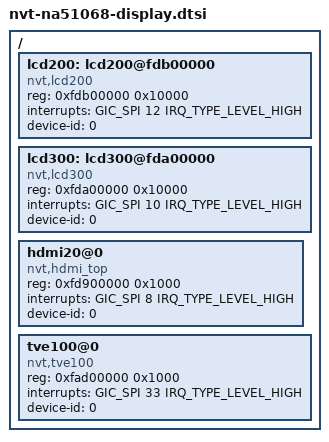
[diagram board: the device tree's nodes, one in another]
/*
 * Novatek Ltd. NA51068 BSP part of dts
 *
 * Cortex-A9
 *
 */

/ {    
    lcd200: lcd200@fdb00000 {
        compatible = "nvt,lcd200";
        reg = <0xfdb00000 0x10000>;
        interrupts = <GIC_SPI 12 IRQ_TYPE_LEVEL_HIGH>;
        device-id = <0>;
    };

    lcd300: lcd300@fda00000 {
		compatible = "nvt,lcd300";
		reg = <0xfda00000 0x10000>;
		interrupts = <GIC_SPI 10 IRQ_TYPE_LEVEL_HIGH>;
		device-id = <0>;
	};
    
    hdmi20@0 {
        compatible = "nvt,hdmi_top";
        reg = <0xfd900000 0x1000>;
        interrupts = <GIC_SPI 8 IRQ_TYPE_LEVEL_HIGH>;
        device-id = <0>;
    };
    
    tve100@0 {
        compatible = "nvt,tve100";
        reg = <0xfad00000 0x1000>;
        interrupts = <GIC_SPI 33 IRQ_TYPE_LEVEL_HIGH>;
        device-id = <0>;
    };
};

